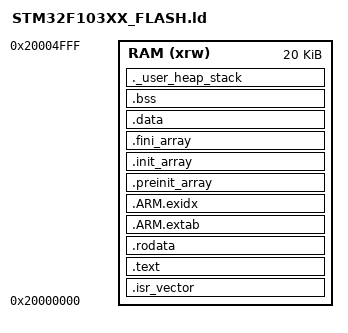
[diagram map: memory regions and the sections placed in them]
/* LinkerScript_RAM.ld - run from SRAM on STM32F103C8 (20KB RAM) */
ENTRY(Reset_Handler)

MEMORY
{
  RAM (xrw) : ORIGIN = 0x20000000, LENGTH = 20K
}

/* Stack at top of RAM */
_estack = ORIGIN(RAM) + LENGTH(RAM);

_Min_Heap_Size  = 0x200;
_Min_Stack_Size = 0x400;

SECTIONS
{
  /* Vector table at start of RAM */
  .isr_vector :
  {
    . = ALIGN(4);
    KEEP(*(.isr_vector))
    . = ALIGN(4);
  } >RAM

  /* Code + RO data in RAM */
  .text :
  {
    . = ALIGN(4);
    *(.text) *(.text*)
    *(.glue_7) *(.glue_7t)
    *(.eh_frame)
    KEEP(*(.init))
    KEEP(*(.fini))
    . = ALIGN(4);
    _etext = .;
  } >RAM

  .rodata :
  {
    . = ALIGN(4);
    *(.rodata) *(.rodata*)
    . = ALIGN(4);
  } >RAM

  .ARM.extab :
  {
    . = ALIGN(4);
    *(.ARM.extab* .gnu.linkonce.armextab.*)
    . = ALIGN(4);
  } >RAM

  .ARM.exidx :
  {
    . = ALIGN(4);
    __exidx_start = .;
    *(.ARM.exidx*)
    __exidx_end = .;
    . = ALIGN(4);
  } >RAM

  .preinit_array :
  {
    . = ALIGN(4);
    PROVIDE_HIDDEN(__preinit_array_start = .);
    KEEP(*(.preinit_array*))
    PROVIDE_HIDDEN(__preinit_array_end = .);
    . = ALIGN(4);
  } >RAM

  .init_array :
  {
    . = ALIGN(4);
    PROVIDE_HIDDEN(__init_array_start = .);
    KEEP(*(SORT(.init_array.*)))
    KEEP(*(.init_array*))
    PROVIDE_HIDDEN(__init_array_end = .);
    . = ALIGN(4);
  } >RAM

  .fini_array :
  {
    . = ALIGN(4);
    PROVIDE_HIDDEN(__fini_array_start = .);
    KEEP(*(SORT(.fini_array.*)))
    KEEP(*(.fini_array*))
    PROVIDE_HIDDEN(__fini_array_end = .);
    . = ALIGN(4);
  } >RAM

  /* Data in RAM (already “loaded” by debugger into RAM) */
  .data :
  {
    . = ALIGN(4);
    _sdata = .;
    *(.data) *(.data*)
    *(.RamFunc) *(.RamFunc*)
    . = ALIGN(4);
    _edata = .;
  } >RAM

  /* For startup code compatibility */
  PROVIDE(_sidata = _sdata);

  /* BSS in RAM */
  .bss (NOLOAD) :
  {
    . = ALIGN(4);
    _sbss = .;
    __bss_start__ = _sbss;
    *(.bss) *(.bss*)
    *(COMMON)
    . = ALIGN(4);
    _ebss = .;
    __bss_end__ = _ebss;
  } >RAM

  /* Heap + stack reservation */
  ._user_heap_stack (NOLOAD) :
  {
    . = ALIGN(8);
    PROVIDE(end = .);
    PROVIDE(_end = .);
    . = . + _Min_Heap_Size;
    . = . + _Min_Stack_Size;
    . = ALIGN(8);
  } >RAM
}
